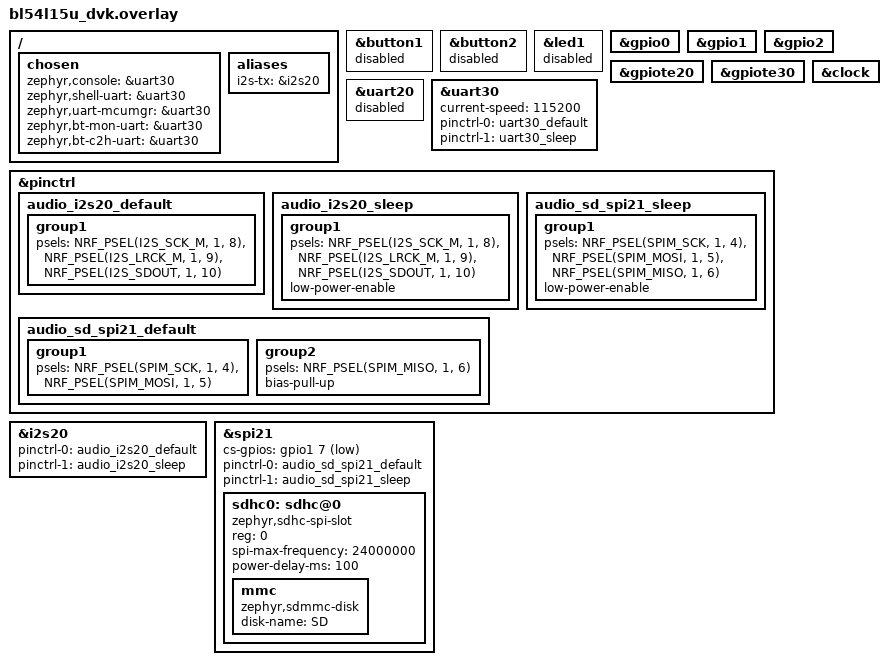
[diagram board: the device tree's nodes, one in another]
#include <zephyr/dt-bindings/gpio/gpio.h>
#include <zephyr/dt-bindings/pinctrl/nrf-pinctrl.h>

/*
 * BL54L15u DVK + Adafruit Audio BFF MAX98357 I2S & MicroSD baseline.
 *
 * I2S amp:
 *   P1.08 -> MAX98357A BCLK
 *   P1.09 -> MAX98357A LRC / WS
 *   P1.10 -> MAX98357A DIN
 *   3V3   -> MAX98357A VIN
 *   GND   -> MAX98357A GND
 *
 * MicroSD SPI pins below use default-connected header pins.
 * Adjust these if your BFF wiring uses different DVK header pins.
 *   P1.04 -> SD SCK
 *   P1.05 -> SD MOSI
 *   P1.06 -> SD MISO
 *   P1.07 -> SD CS
 */

/ {
    chosen {
        zephyr,console = &uart30;
        zephyr,shell-uart = &uart30;
        zephyr,uart-mcumgr = &uart30;
        zephyr,bt-mon-uart = &uart30;
        zephyr,bt-c2h-uart = &uart30;
    };

    aliases {
        i2s-tx = &i2s20;
    };
};

&button1 { status = "disabled"; };  /* P1.09 */
&button2 { status = "disabled"; };  /* P1.08 */
&led1 { status = "disabled"; };     /* P1.10 */

&gpio0 { status = "okay"; };
&gpio1 { status = "okay"; };
&gpio2 { status = "okay"; };
&gpiote20 { status = "okay"; };
&gpiote30 { status = "okay"; };
&clock { status = "okay"; };

&uart20 {
    status = "disabled";
};

&uart30 {
    status = "okay";
    current-speed = <115200>;
    pinctrl-0 = <&uart30_default>;
    pinctrl-1 = <&uart30_sleep>;
    pinctrl-names = "default", "sleep";
};

&pinctrl {
    audio_i2s20_default: audio_i2s20_default {
        group1 {
            psels = <NRF_PSEL(I2S_SCK_M, 1, 8)>,
                    <NRF_PSEL(I2S_LRCK_M, 1, 9)>,
                    <NRF_PSEL(I2S_SDOUT, 1, 10)>;
        };
    };

    audio_i2s20_sleep: audio_i2s20_sleep {
        group1 {
            psels = <NRF_PSEL(I2S_SCK_M, 1, 8)>,
                    <NRF_PSEL(I2S_LRCK_M, 1, 9)>,
                    <NRF_PSEL(I2S_SDOUT, 1, 10)>;
            low-power-enable;
        };
    };

    audio_sd_spi21_default: audio_sd_spi21_default {
        group1 {
            psels = <NRF_PSEL(SPIM_SCK, 1, 4)>,
                    <NRF_PSEL(SPIM_MOSI, 1, 5)>;
        };

        group2 {
            psels = <NRF_PSEL(SPIM_MISO, 1, 6)>;
            bias-pull-up;
        };
    };

    audio_sd_spi21_sleep: audio_sd_spi21_sleep {
        group1 {
            psels = <NRF_PSEL(SPIM_SCK, 1, 4)>,
                    <NRF_PSEL(SPIM_MOSI, 1, 5)>,
                    <NRF_PSEL(SPIM_MISO, 1, 6)>;
            low-power-enable;
        };
    };
};

&i2s20 {
    status = "okay";
    pinctrl-0 = <&audio_i2s20_default>;
    pinctrl-1 = <&audio_i2s20_sleep>;
    pinctrl-names = "default", "sleep";
};

&spi21 {
    status = "okay";
    cs-gpios = <&gpio1 7 GPIO_ACTIVE_LOW>;
    pinctrl-0 = <&audio_sd_spi21_default>;
    pinctrl-1 = <&audio_sd_spi21_sleep>;
    pinctrl-names = "default", "sleep";

    sdhc0: sdhc@0 {
        compatible = "zephyr,sdhc-spi-slot";
        reg = <0>;
        status = "okay";
        spi-max-frequency = <24000000>;
        power-delay-ms = <100>;

        mmc {
            compatible = "zephyr,sdmmc-disk";
            disk-name = "SD";
            status = "okay";
        };
    };
};
